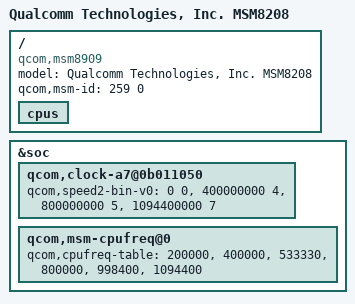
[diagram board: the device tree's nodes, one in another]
/*
 * Copyright (c) 2014, The Linux Foundation. All rights reserved.
 *
 * This program is free software; you can redistribute it and/or modify
 * it under the terms of the GNU General Public License version 2 and
 * only version 2 as published by the Free Software Foundation.
 *
 * This program is distributed in the hope that it will be useful,
 * but WITHOUT ANY WARRANTY; without even the implied warranty of
 * MERCHANTABILITY or FITNESS FOR A PARTICULAR PURPOSE.  See the
 * GNU General Public License for more details.
 */

/ {
	model = "Qualcomm Technologies, Inc. MSM8208";
	compatible = "qcom,msm8909";
	qcom,msm-id =   <259 0>;

	cpus {
		/delete-node/ cpu@2;
		/delete-node/ cpu@3;
	};
};

&soc {
	/delete-node/ jtagmm@84e000;
	/delete-node/ jtagmm@84f000;
	/delete-node/ qcom,spm@b0a9000;
	/delete-node/ qcom,spm@b0b9000;
	/delete-node/ cti@853000;
	/delete-node/ cti@854000;
	/delete-node/ etm@84e000;
	/delete-node/ etm@84f000;

	qcom,clock-a7@0b011050 {
		qcom,speed2-bin-v0 =
			<          0 0>,
			<  400000000 4>,
			<  800000000 5>,
			< 1094400000 7>;
	};

	qcom,msm-cpufreq@0 {
		qcom,cpufreq-table =
			 <  200000 >,
			 <  400000 >,
			 <  533330 >,
			 <  800000 >,
			 <  998400 >,
			 < 1094400 >;
	};
};

